# ADSP-2183xW_LPC register map
Vendor: Analog Devices; Series: ADSP-2183xW_LPC; File version: 3.0.3.517
CPU: 
Registers are 32-bit, read-write, reset 0x0 unless marked. A register's access mark holds for its fields unless they carry their own. Offsets are from the block's base; [hi:lo] are bit positions; {n}, {i} and the like mark numbered series.

## MLB0 — MediaLB Device Interface Macro 2
Base 0x3109D000
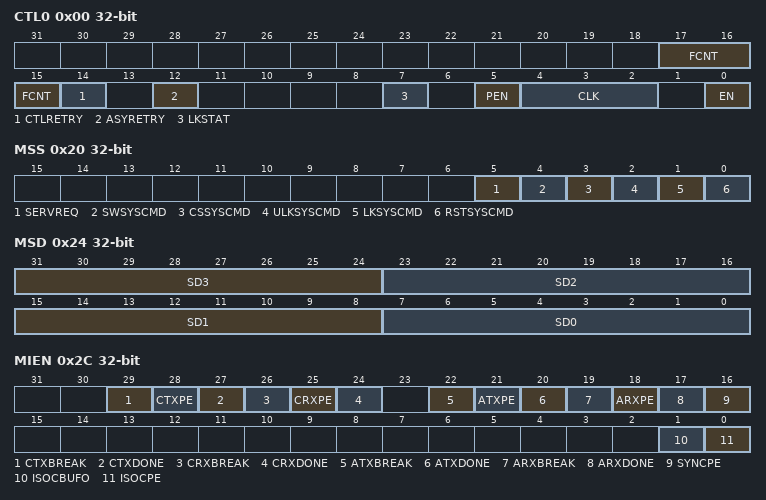
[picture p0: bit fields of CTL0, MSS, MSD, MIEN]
0x00 CTL0 — MediaLB Control 0 Register
  [17:15] FCNT — Frames Per Sub-buffer
  [14] CTLRETRY range 0x00000000..0x00000001 — Control Tx Packet Retry
  [12] ASYRETRY range 0x00000000..0x00000001 — Asynchronous Tx Packet Retry
  [7] LKSTAT ro — Lock Status
  [5] PEN — 3-pin Enable
  [4:2] CLK — Clock Speed Select
  [0] EN range 0x00000000..0x00000001 — Enable
0x0C MS0 — Channel Status 0 Register
  [31:0] MCS range 0x00000000..0xFFFFFFFF — MediaLB Channel Status
0x14 MS1 — Channel Status 1 Register
  [31:0] MCS range 0x00000000..0xFFFFFFFF — MediaLB Channel Status
0x20 MSS — System Status Register
  [5] SERVREQ range 0x00000000..0x00000001 — Service Request Enable
  [4] SWSYSCMD range 0x00000000..0x00000001 — Software System Command Detected
  [3] CSSYSCMD range 0x00000000..0x00000001 — Channel Scan System Command Detected
  [2] ULKSYSCMD range 0x00000000..0x00000001 — Network Unlock System Command Detected
  [1] LKSYSCMD range 0x00000000..0x00000001 — Network Lock System Command Detected
  [0] RSTSYSCMD range 0x00000000..0x00000001 — Reset System Command Detected
0x24 MSD — System Data Register
  [31:24] SD3 ro — System Data Byte 3 (MSB)
  [23:16] SD2 ro — System Data Byte 2
  [15:8] SD1 ro — System Data Byte 1
  [7:0] SD0 ro — System Data Byte 0 (LSB)
0x2C MIEN — Interrupt Enable Register
  [29] CTXBREAK range 0x00000000..0x00000001 — Control Transmit Break Enable
  [28] CTXPE range 0x00000000..0x00000001 — Control Transmit Protocol Error Enable
  [27] CTXDONE range 0x00000000..0x00000001 — Control Transmit Packet Done Enable
  [26] CRXBREAK range 0x00000000..0x00000001 — Control Receive Break Enable
  [25] CRXPE range 0x00000000..0x00000001 — Control Receive Protocol Error Enable
  [24] CRXDONE range 0x00000000..0x00000001 — Control Receive Packet Done Enable
  [22] ATXBREAK range 0x00000000..0x00000001 — Asynchronous Transmit Break Enable
  [21] ATXPE range 0x00000000..0x00000001 — Asynchronous Transmit Protocol Error Enable
  [20] ATXDONE range 0x00000000..0x00000001 — Asynchronous Transmit Done Enable
  [19] ARXBREAK range 0x00000000..0x00000001 — Asynchronous Receive Break Enable
  [18] ARXPE range 0x00000000..0x00000001 — Asynchronous Receive Protocol Error Enable
  [17] ARXDONE range 0x00000000..0x00000001 — Asynchronous Receive Packet Done Enable
  [16] SYNCPE range 0x00000000..0x00000001 — Synchronous Protocol Error Enable
  [1] ISOCBUFO range 0x00000000..0x00000001 — Isochronous Receive Buffer Overflow Enable
  [0] ISOCPE range 0x00000000..0x00000001 — Isochronous Receive Protocol Error Enable
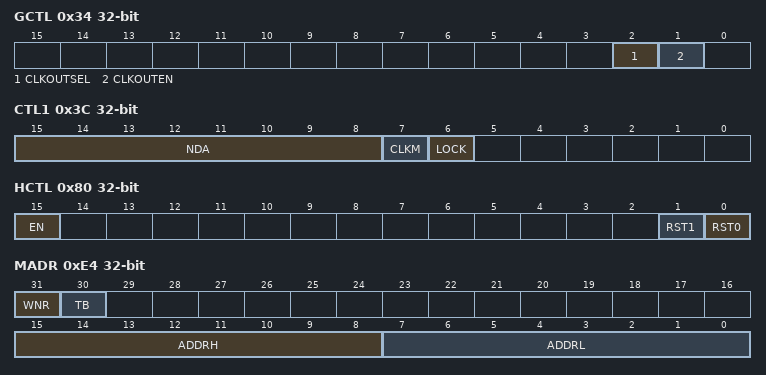
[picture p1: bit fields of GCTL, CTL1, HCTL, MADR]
0x34 GCTL — MLB Global Control Register
  [2] CLKOUTSEL — CLKOUT Select
  [1] CLKOUTEN range 0x00000000..0x00000001 — CLKOUT Enable
0x3C CTL1 — Control 1 Register
  [15:8] NDA range 0x00000000..0x000000FF — Node Device Address
  [7] CLKM range 0x00000000..0x00000001 — Lock Missing Status
  [6] LOCK range 0x00000000..0x00000001 — Lock Error Status
0x80 HCTL — HBI Control Register
  [15] EN range 0x00000000..0x00000001 — HBI Enable
  [1] RST1 range 0x00000000..0x00000001 — AGU1 Software Reset
  [0] RST0 range 0x00000000..0x00000001 — AGU0 Software Reset
0x88 HCMR0 — HBI Channel Mask 0 Register
  [31:0] CHM range 0x00000000..0xFFFFFFFF — Channel Mask
0x8C HCMR1 — HBI Channel Mask 1 Register
  [31:0] CHM range 0x00000000..0xFFFFFFFF — Bitwise channel mask bit for channels 63:32
0x90 HCER0 — HBI Channel Error 0 Register
  [31:0] CERR range 0x00000000..0xFFFFFFFF — Channel Error
0x94 HCER1 — HBI Channel Error 1 Register
  [31:0] CERR range 0x00000000..0xFFFFFFFF — Channel Error
0x98 HCBR0 — HBI Channel Busy 0 Register
  [31:0] CHB ro — Channel Busy
0x9C HCBR1 — HBI Channel Busy 1 Register
  [31:0] CHB ro — Channel Busy
{0xC0+4i} MDAT{i} (i=0..3) — Memory Interface Control Data {i} Register
  [31:0] DATA range 0x00000000..0xFFFFFFFF
0xD0 MDWE0 — Memory Interface Control Data Write Enable 0 Register
  [31:0] MSK range 0x00000000..0xFFFFFFFF — Write Enable
{0xD0+4i} MDWE{i} (i=1..3) — Memory Interface Control Data Write Enable {i} Register
  [31:0] MSK range 0x00000000..0xFFFFFFFF — Bitwise write enable for CTR data - bits[{32i+31}:{32i}]
0xE0 MCTL — Memory Interface Control Register
  [0] XCMP range 0x00000000..0x00000001 — Transfer Complete (Write 0 to clear)
0xE4 MADR — Memory Interface Address Register
  [31] WNR — Write-Not-Read
  [30] TB — Target Bit
  [15:8] ADDRH range 0x00000000..0x000000FF — Address Higher Bits
  [7:0] ADDRL range 0x00000000..0x000000FF — Address Lower Bits
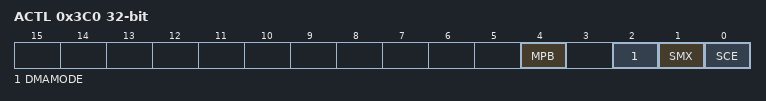
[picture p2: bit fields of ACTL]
0x3C0 ACTL — Bus Control Register
  [4] MPB — Packet Buffering Mode
  [2] DMAMODE
  [1] SMX — Interrupt Multiplex Enable
  [0] SCE — Software Clear Enable
0x3D0 ACSR0 — Peripheral Channel Status 0 Register
  [31:0] CHS — Channel Status
0x3D4 ACSR1 — Peripheral Channel Status 1 Register
  [31:0] CHS — Channel Status
0x3D8 ACMR0 — Peripheral Channel Mask 0 Register
  [31:0] CHM — Bitwise Channel Mask
0x3DC ACMR1 — Peripheral Channel Mask 1 Register
  [31:0] CHM — Bitwise Channel Mask
